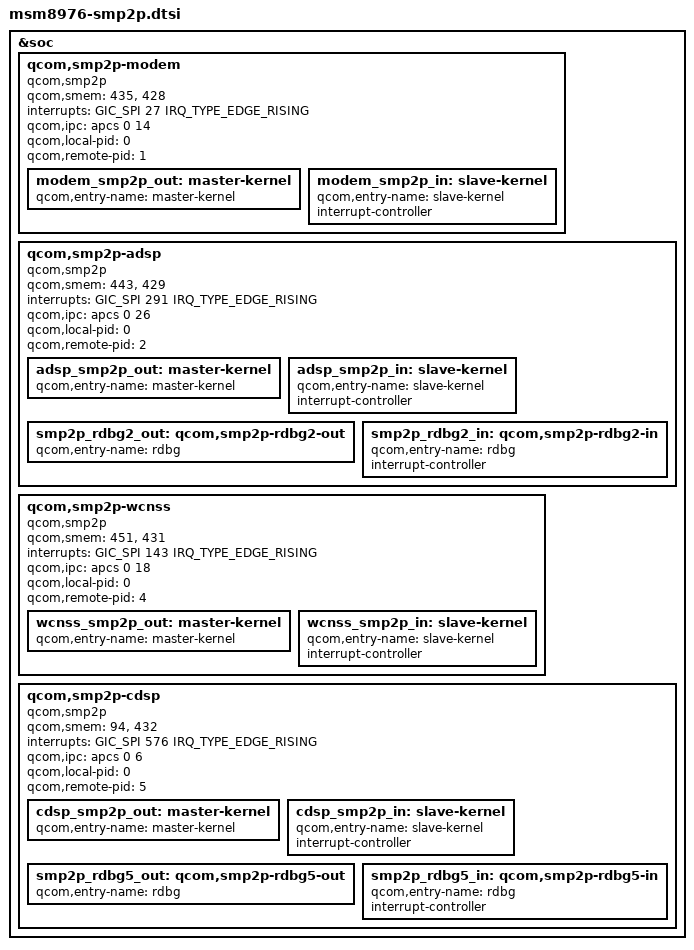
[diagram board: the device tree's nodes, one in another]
// SPDX-License-Identifier: GPL-2.0
// Copyright (c) 2015, The Linux Foundation. All rights reserved.
// Copyright (c) 2023, Benarji Anand <benarji385@gmail.com>

#include <dt-bindings/interrupt-controller/arm-gic.h>

&soc {
	qcom,smp2p-modem {
		compatible = "qcom,smp2p";
		qcom,smem = <435>, <428>;
		interrupts = <GIC_SPI 27 IRQ_TYPE_EDGE_RISING>;
		qcom,ipc = <&apcs 0 14>;
		qcom,local-pid = <0>;
		qcom,remote-pid = <1>;

		modem_smp2p_out: master-kernel {
			qcom,entry-name = "master-kernel";
			#qcom,smem-state-cells = <1>;
		};

		modem_smp2p_in: slave-kernel {
			qcom,entry-name = "slave-kernel";
			interrupt-controller;
			#interrupt-cells = <2>;
		};
	};

	qcom,smp2p-adsp {
		compatible = "qcom,smp2p";
		qcom,smem = <443>, <429>;
		interrupts = <GIC_SPI 291 IRQ_TYPE_EDGE_RISING>;
		qcom,ipc = <&apcs 0 26>;
		qcom,local-pid = <0>;
		qcom,remote-pid = <2>;

		adsp_smp2p_out: master-kernel {
			qcom,entry-name = "master-kernel";
			#qcom,smem-state-cells = <1>;
		};

		adsp_smp2p_in: slave-kernel {
			qcom,entry-name = "slave-kernel";
			interrupt-controller;
			#interrupt-cells = <2>;
		};

		smp2p_rdbg2_out: qcom,smp2p-rdbg2-out {
			qcom,entry-name = "rdbg";
			#qcom,smem-state-cells = <1>;
		};

		smp2p_rdbg2_in: qcom,smp2p-rdbg2-in {
			qcom,entry-name = "rdbg";
			interrupt-controller;
			#interrupt-cells = <2>;
		};
	};

	qcom,smp2p-wcnss {
		compatible = "qcom,smp2p";
		qcom,smem = <451>, <431>;
		interrupts = <GIC_SPI 143 IRQ_TYPE_EDGE_RISING>;
 		qcom,ipc = <&apcs 0 18>;
		qcom,local-pid = <0>;
		qcom,remote-pid = <4>;

		wcnss_smp2p_out: master-kernel {
			qcom,entry-name = "master-kernel";
			#qcom,smem-state-cells = <1>;
		};

		wcnss_smp2p_in: slave-kernel {
			qcom,entry-name = "slave-kernel";
			interrupt-controller;
			#interrupt-cells = <2>;
		};
	};

	qcom,smp2p-cdsp {
		compatible = "qcom,smp2p";
		qcom,smem = <94>, <432>;
		interrupts = <GIC_SPI 576 IRQ_TYPE_EDGE_RISING>;
		qcom,ipc = <&apcs 0 6>;
		qcom,local-pid = <0>;
		qcom,remote-pid = <5>;

		cdsp_smp2p_out: master-kernel {
			qcom,entry-name = "master-kernel";
			#qcom,smem-state-cells = <1>;
		};

		cdsp_smp2p_in: slave-kernel {
			qcom,entry-name = "slave-kernel";
			interrupt-controller;
			#interrupt-cells = <2>;
		};

		smp2p_rdbg5_out: qcom,smp2p-rdbg5-out {
			qcom,entry-name = "rdbg";
			#qcom,smem-state-cells = <1>;
		};

		smp2p_rdbg5_in: qcom,smp2p-rdbg5-in {
			qcom,entry-name = "rdbg";
			interrupt-controller;
			#interrupt-cells = <2>;
		};
        };
};
